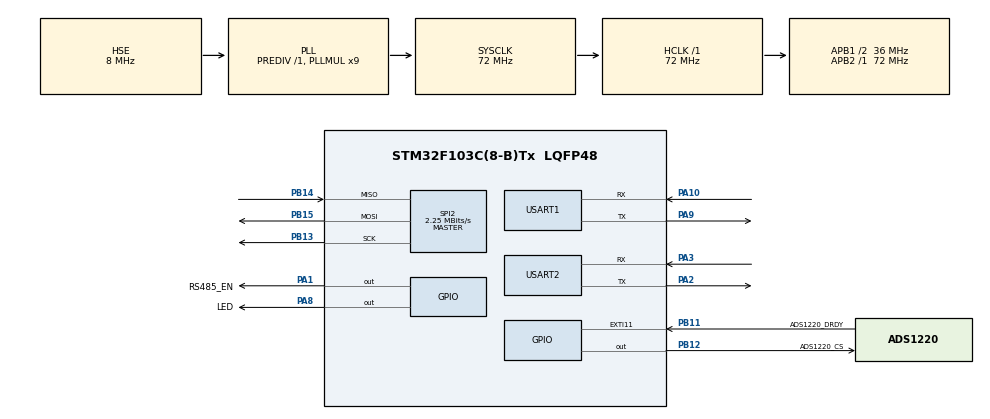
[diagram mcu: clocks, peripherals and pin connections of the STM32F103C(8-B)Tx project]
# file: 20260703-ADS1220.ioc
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Mcu.Family=STM32F1
Mcu.Name=STM32F103C(8-B)Tx
Mcu.Package=LQFP48
NVIC.EXTI15_10_IRQn=true\:1\:0\:true\:false\:true\:true\:true\:true
NVIC.PriorityGroup=NVIC_PRIORITYGROUP_4
NVIC.TIM2_IRQn=true\:0\:0\:false\:false\:true\:true\:true\:true
NVIC.USART1_IRQn=true\:0\:0\:false\:false\:true\:true\:true\:true
NVIC.USART2_IRQn=true\:0\:0\:false\:false\:true\:true\:true\:true
PA1.GPIO_Label=RS485_EN
PA1.GPIO_PuPd=GPIO_NOPULL
PA1.Signal=GPIO_Output
PA10.Mode=Asynchronous
PA10.Signal=USART1_RX
PA13.Mode=Serial_Wire
PA13.Signal=SYS_JTMS-SWDIO
PA14.Mode=Serial_Wire
PA14.Signal=SYS_JTCK-SWCLK
PA2.Mode=Asynchronous
PA2.Signal=USART2_TX
PA3.Mode=Asynchronous
PA3.Signal=USART2_RX
PA8.GPIO_Label=LED
PA8.Signal=GPIO_Output
PA9.Mode=Asynchronous
PA9.Signal=USART1_TX
PB11.GPIO_Label=ADS1220_DRDY
PB11.GPIO_ModeDefaultEXTI=GPIO_MODE_IT_FALLING
PB11.GPIO_PuPd=GPIO_PULLUP
PB11.Signal=GPXTI11
PB12.GPIO_Label=ADS1220_CS
PB12.GPIO_ModeDefaultOutputPP=GPIO_MODE_OUTPUT_PP
PB12.GPIO_PuPd=GPIO_NOPULL
PB12.PinState=GPIO_PIN_SET
PB12.Signal=GPIO_Output
PB13.Mode=Full_Duplex_Master
PB13.Signal=SPI2_SCK
PB14.Mode=Full_Duplex_Master
PB14.Signal=SPI2_MISO
PB15.Mode=Full_Duplex_Master
PB15.Signal=SPI2_MOSI
PD0-OSC_IN.Mode=HSE-External-Oscillator
PD0-OSC_IN.Signal=RCC_OSC_IN
PD1-OSC_OUT.Mode=HSE-External-Oscillator
PD1-OSC_OUT.Signal=RCC_OSC_OUT
ProjectManager.HeapSize=0x200
ProjectManager.StackSize=0x400
ProjectManager.TargetToolchain=MDK-ARM V5.32
RCC.AHBFreq_Value=72000000
RCC.APB1CLKDivider=RCC_HCLK_DIV2
RCC.APB1Freq_Value=36000000
RCC.APB1TimFreq_Value=72000000
RCC.APB2Freq_Value=72000000
RCC.APB2TimFreq_Value=72000000
RCC.HCLKFreq_Value=72000000
RCC.PLLMUL=RCC_PLL_MUL9
RCC.PLLSourceVirtual=RCC_PLLSOURCE_HSE
RCC.SYSCLKFreq_VALUE=72000000
RCC.SYSCLKSource=RCC_SYSCLKSOURCE_PLLCLK
RCC.USBFreq_Value=72000000
SPI2.BaudRatePrescaler=SPI_BAUDRATEPRESCALER_16
SPI2.CLKPhase=SPI_PHASE_2EDGE
SPI2.CalculateBaudRate=2.25 MBits/s
SPI2.Direction=SPI_DIRECTION_2LINES
SPI2.Mode=SPI_MODE_MASTER
SPI2.VirtualType=VM_MASTER
TIM2.Period=1749
TIM2.Prescaler=71
USART1.VirtualMode=VM_ASYNC
USART2.Parity=PARITY_EVEN
USART2.VirtualMode=VM_ASYNC
USART2.WordLength=WORDLENGTH_9B
VP_TIM2_VS_ClockSourceINT.Mode=Internal
board=custom

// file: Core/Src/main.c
/* USER CODE BEGIN Header */
/**
  ******************************************************************************
  * @file           : main.c
  * @brief          : ADS1220 Wheatstone Bridge ADC Reader
  *
  * @note           本文件只保留 HAL 初始化、时钟配置与错误处理。
  *                  业务逻辑位于 App/ 目录：
  *                    app.c         应用初始化与主循环调度
  *                    app_config.h  唯一配置源（增益/速率/滤波/去皮等）
  *                    app_measure.c 采集状态机
  *                    app_shell.c   串口命令解析
  *                    app_report.c  调试输出
  ******************************************************************************
  */
/* USER CODE END Header */
#include "main.h"
#include "spi.h"
#include "tim.h"
#include "usart.h"
#include "gpio.h"

/* USER CODE BEGIN Includes */
#include "app.h"
/* USER CODE END Includes */

void SystemClock_Config(void);

int main(void)
{

  /* MCU Configuration--------------------------------------------------------*/

  /* Reset of all peripherals, Initializes the Flash interface and the Systick. */
  HAL_Init();

  /* Configure the system clock */
  SystemClock_Config();

  /* Initialize all configured peripherals */
  MX_GPIO_Init();
  MX_USART1_UART_Init();
  MX_SPI2_Init();
  MX_USART2_UART_Init();
  MX_TIM2_Init();
  /* USER CODE BEGIN 2 */
  App_Init();   /* ADS1220 自检 + 串口 shell（CubeMX 10-20 重生成时被清空，此处恢复） */
  /* USER CODE END 2 */

  /* Infinite loop */
  /* USER CODE BEGIN WHILE */
  while (1)
  {
    App_Loop();   /* 采集/输出/LED 心跳喂狗 */
    /* USER CODE END WHILE */

  }
}

void SystemClock_Config(void)
{
  RCC_OscInitTypeDef RCC_OscInitStruct = {0};
  RCC_ClkInitTypeDef RCC_ClkInitStruct = {0};

  /** Initializes the RCC Oscillators according to the specified parameters
  * in the RCC_OscInitTypeDef structure.
  */
  RCC_OscInitStruct.OscillatorType = RCC_OSCILLATORTYPE_HSE;
  RCC_OscInitStruct.HSEState = RCC_HSE_ON;
  RCC_OscInitStruct.HSEPredivValue = RCC_HSE_PREDIV_DIV1;
  RCC_OscInitStruct.HSIState = RCC_HSI_ON;
  RCC_OscInitStruct.PLL.PLLState = RCC_PLL_ON;
  RCC_OscInitStruct.PLL.PLLSource = RCC_PLLSOURCE_HSE;
  RCC_OscInitStruct.PLL.PLLMUL = RCC_PLL_MUL9;
  if (HAL_RCC_OscConfig(&RCC_OscInitStruct) != HAL_OK)
  {
    Error_Handler();
  }

  /** Initializes the CPU, AHB and APB buses clocks
  */
  RCC_ClkInitStruct.ClockType = RCC_CLOCKTYPE_HCLK|RCC_CLOCKTYPE_SYSCLK
                              |RCC_CLOCKTYPE_PCLK1|RCC_CLOCKTYPE_PCLK2;
  RCC_ClkInitStruct.SYSCLKSource = RCC_SYSCLKSOURCE_PLLCLK;
  RCC_ClkInitStruct.AHBCLKDivider = RCC_SYSCLK_DIV1;
  RCC_ClkInitStruct.APB1CLKDivider = RCC_HCLK_DIV2;
  RCC_ClkInitStruct.APB2CLKDivider = RCC_HCLK_DIV1;

  if (HAL_RCC_ClockConfig(&RCC_ClkInitStruct, FLASH_LATENCY_2) != HAL_OK)
  {
    Error_Handler();
  }
}

void Error_Handler(void)
{
  __disable_irq();
  while (1)
  {
  }
}
